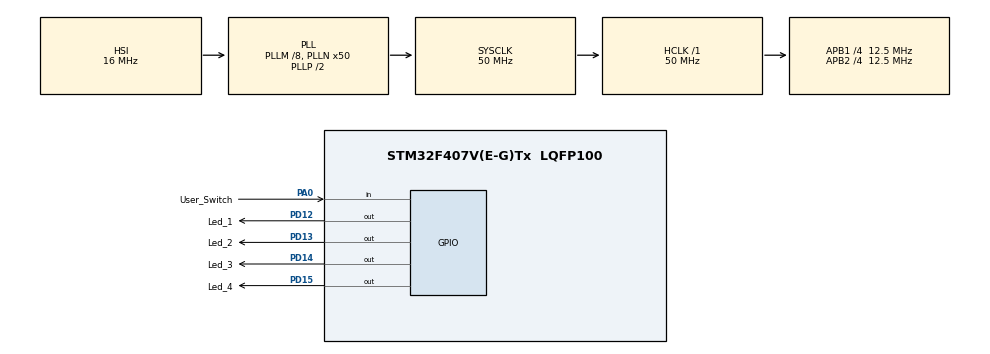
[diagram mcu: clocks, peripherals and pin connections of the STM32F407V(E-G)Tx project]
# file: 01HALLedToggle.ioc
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Mcu.Family=STM32F4
Mcu.Name=STM32F407V(E-G)Tx
Mcu.Package=LQFP100
NVIC.PriorityGroup=NVIC_PRIORITYGROUP_0
PA0-WKUP.GPIO_Label=User_Switch
PA0-WKUP.Signal=GPIO_Input
PD12.GPIO_Label=Led_1
PD12.Signal=GPIO_Output
PD13.GPIO_Label=Led_2
PD13.Signal=GPIO_Output
PD14.GPIO_Label=Led_3
PD14.Signal=GPIO_Output
PD15.GPIO_Label=Led_4
PD15.Signal=GPIO_Output
ProjectManager.HeapSize=0x200
ProjectManager.StackSize=0x400
ProjectManager.TargetToolchain=STM32CubeIDE
RCC.48MHZClocksFreq_Value=14285714.285714285
RCC.AHBFreq_Value=50000000
RCC.APB1CLKDivider=RCC_HCLK_DIV4
RCC.APB1Freq_Value=12500000
RCC.APB1TimFreq_Value=25000000
RCC.APB2CLKDivider=RCC_HCLK_DIV4
RCC.APB2Freq_Value=12500000
RCC.APB2TimFreq_Value=25000000
RCC.CortexFreq_Value=50000000
RCC.HCLKFreq_Value=50000000
RCC.HSE_VALUE=8000000
RCC.HSI_VALUE=16000000
RCC.PLLM=8
RCC.PLLN=50
RCC.PLLQ=7
RCC.SYSCLKFreq_VALUE=50000000
RCC.SYSCLKSource=RCC_SYSCLKSOURCE_PLLCLK
RCC.VCOOutputFreq_Value=100000000
board=STM32F407G-DISC1

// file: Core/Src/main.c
/* USER CODE BEGIN Header */
/**
  ******************************************************************************
  * @file           : main.c
  * @brief          : Main program body
  ******************************************************************************
  * @attention
  *
  * <h2><center>&copy; Copyright (c) 2020 STMicroelectronics.
  * All rights reserved.</center></h2>
  *
  * This software component is licensed by ST under Ultimate Liberty license
  * SLA0044, the "License"; You may not use this file except in compliance with
  * the License. You may obtain a copy of the License at:
  *                             www.st.com/SLA0044
  *
  ******************************************************************************
  */
/* USER CODE END Header */
#include "main.h"

void SystemClock_Config(void);
static void MX_GPIO_Init(void);
/* USER CODE BEGIN PFP */
void delay(void)
{
	for(uint32_t T = 0; T < 200000; T++)
	{
		//DO NOTHING
	}
}
/* USER CODE END PFP */

int main(void)
{

  /* MCU Configuration--------------------------------------------------------*/

  /* Reset of all peripherals, Initializes the Flash interface and the Systick. */
  HAL_Init();

  /* Configure the system clock */
  SystemClock_Config();

  /* Initialize all configured peripherals */
  MX_GPIO_Init();

  /* Infinite loop */
  while (1)
  {
	  if(HAL_GPIO_ReadPin(GPIOA, User_Switch_Pin))
	  {
		  HAL_GPIO_WritePin(GPIOD, Led_1_Pin, ENABLE);
		  delay();
		  HAL_GPIO_WritePin(GPIOD, Led_2_Pin, ENABLE);
		  delay();
		  HAL_GPIO_WritePin(GPIOD, Led_3_Pin, ENABLE);
		  delay();
		  HAL_GPIO_WritePin(GPIOD, Led_4_Pin, ENABLE);
		  delay();
	  }
	  else
	  {
		  HAL_GPIO_WritePin(GPIOD, Led_1_Pin, DISABLE);
		  delay();
		  HAL_GPIO_WritePin(GPIOD, Led_2_Pin, DISABLE);
		  delay();
		  HAL_GPIO_WritePin(GPIOD, Led_3_Pin, DISABLE);
		  delay();
		  HAL_GPIO_WritePin(GPIOD, Led_4_Pin, DISABLE);
		  delay();
	  }
  }
}

void SystemClock_Config(void)
{
  RCC_OscInitTypeDef RCC_OscInitStruct = {0};
  RCC_ClkInitTypeDef RCC_ClkInitStruct = {0};

  /** Configure the main internal regulator output voltage
  */
  __HAL_RCC_PWR_CLK_ENABLE();
  __HAL_PWR_VOLTAGESCALING_CONFIG(PWR_REGULATOR_VOLTAGE_SCALE1);
  /** Initializes the RCC Oscillators according to the specified parameters
  * in the RCC_OscInitTypeDef structure.
  */
  RCC_OscInitStruct.OscillatorType = RCC_OSCILLATORTYPE_HSI;
  RCC_OscInitStruct.HSIState = RCC_HSI_ON;
  RCC_OscInitStruct.HSICalibrationValue = RCC_HSICALIBRATION_DEFAULT;
  RCC_OscInitStruct.PLL.PLLState = RCC_PLL_ON;
  RCC_OscInitStruct.PLL.PLLSource = RCC_PLLSOURCE_HSI;
  RCC_OscInitStruct.PLL.PLLM = 8;
  RCC_OscInitStruct.PLL.PLLN = 50;
  RCC_OscInitStruct.PLL.PLLP = RCC_PLLP_DIV2;
  RCC_OscInitStruct.PLL.PLLQ = 7;
  if (HAL_RCC_OscConfig(&RCC_OscInitStruct) != HAL_OK)
  {
    Error_Handler();
  }
  /** Initializes the CPU, AHB and APB buses clocks
  */
  RCC_ClkInitStruct.ClockType = RCC_CLOCKTYPE_HCLK|RCC_CLOCKTYPE_SYSCLK
                              |RCC_CLOCKTYPE_PCLK1|RCC_CLOCKTYPE_PCLK2;
  RCC_ClkInitStruct.SYSCLKSource = RCC_SYSCLKSOURCE_PLLCLK;
  RCC_ClkInitStruct.AHBCLKDivider = RCC_SYSCLK_DIV1;
  RCC_ClkInitStruct.APB1CLKDivider = RCC_HCLK_DIV4;
  RCC_ClkInitStruct.APB2CLKDivider = RCC_HCLK_DIV4;

  if (HAL_RCC_ClockConfig(&RCC_ClkInitStruct, FLASH_LATENCY_1) != HAL_OK)
  {
    Error_Handler();
  }
}

static void MX_GPIO_Init(void)
{
  GPIO_InitTypeDef GPIO_InitStruct = {0};

  /* GPIO Ports Clock Enable */
  __HAL_RCC_GPIOA_CLK_ENABLE();
  __HAL_RCC_GPIOD_CLK_ENABLE();

  /*Configure GPIO pin Output Level */
  HAL_GPIO_WritePin(GPIOD, Led_1_Pin|Led_2_Pin|Led_3_Pin|Led_4_Pin, GPIO_PIN_RESET);

  /*Configure GPIO pin : User_Switch_Pin */
  GPIO_InitStruct.Pin = User_Switch_Pin;
  GPIO_InitStruct.Mode = GPIO_MODE_INPUT;
  GPIO_InitStruct.Pull = GPIO_NOPULL;
  HAL_GPIO_Init(User_Switch_GPIO_Port, &GPIO_InitStruct);

  /*Configure GPIO pins : Led_1_Pin Led_2_Pin Led_3_Pin Led_4_Pin */
  GPIO_InitStruct.Pin = Led_1_Pin|Led_2_Pin|Led_3_Pin|Led_4_Pin;
  GPIO_InitStruct.Mode = GPIO_MODE_OUTPUT_PP;
  GPIO_InitStruct.Pull = GPIO_NOPULL;
  GPIO_InitStruct.Speed = GPIO_SPEED_FREQ_LOW;
  HAL_GPIO_Init(GPIOD, &GPIO_InitStruct);

}

void Error_Handler(void)
{
}

/************************ (C) COPYRIGHT STMicroelectronics *****END OF FILE****/
